AUTOSAR XML (schema 00048)
package /MICROSAR/PwmIf/ComponentTypes
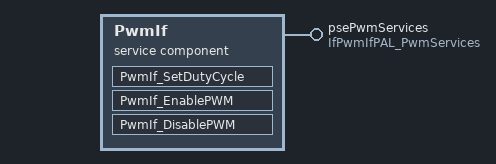
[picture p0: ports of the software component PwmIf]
  service sw component type PwmIf
    provide port psePwmServices: provided-interface=IfPwmIfPAL_PwmServices
      provided-com-specs:
        operation=SetDutyCycle, queue-length=1
        operation=EnablePWM, queue-length=1
        operation=DisablePWM, queue-length=1
    behavior PwmIf_InternalBehavior
      operation invoked event OIT_psePwmServices_SetDutyCycle_psePwmServices_SetDutyCycle: start-on-event=PwmIf_SetDutyCycle, operation=psePwmServices.SetDutyCycle
      operation invoked event OIT_psePwmServices_EnablePWM_psePwmServices_EnablePWM: start-on-event=PwmIf_EnablePWM, operation=psePwmServices.EnablePWM
      operation invoked event OIT_psePwmServices_DisablePWM_psePwmServices_DisablePWM: start-on-event=PwmIf_DisablePWM, operation=psePwmServices.DisablePWM
      runnable PwmIf_SetDutyCycle
      runnable PwmIf_EnablePWM
      runnable PwmIf_DisablePWM
  swc implementation PwmIf_Implementation: behavior=PwmIf_InternalBehavior
